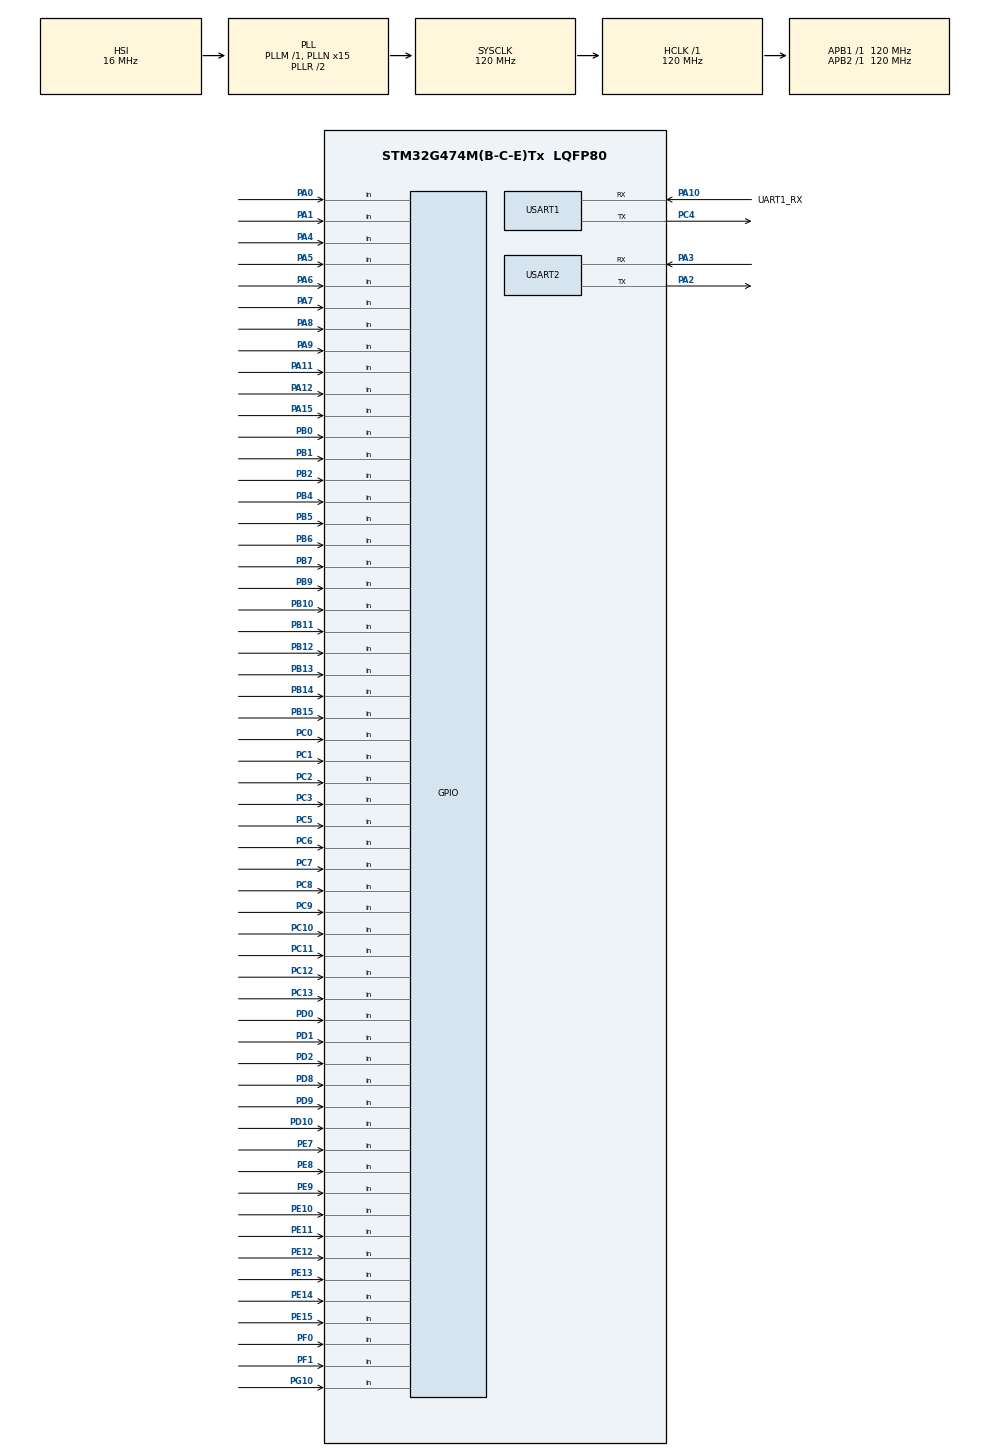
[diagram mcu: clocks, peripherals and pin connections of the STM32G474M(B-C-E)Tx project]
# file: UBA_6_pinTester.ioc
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FATFS._CODE_PAGE=850
FATFS._FS_NORTC=1
FATFS._FS_TINY=0
FATFS._MAX_SS=512
FATFS._MIN_SS=512
Mcu.Family=STM32G4
Mcu.Name=STM32G474M(B-C-E)Tx
Mcu.Package=LQFP80
NVIC.PriorityGroup=NVIC_PRIORITYGROUP_4
NVIC.USART2_IRQn=true\:0\:0\:false\:false\:true\:true\:true\:true
PA0.GPIO_Mode=GPIO_MODE_INPUT
PA0.GPIO_PuPd=GPIO_NOPULL
PA0.Signal=GPIO_Input
PA1.Signal=GPIO_Input
PA10.GPIO_Label=UART1_RX
PA10.Mode=Asynchronous
PA10.Signal=USART1_RX
PA11.Signal=GPIO_Input
PA12.Signal=GPIO_Input
PA13.GPIO_Label=SWDIO
PA13.Mode=Serial_Wire
PA13.Signal=SYS_JTMS-SWDIO
PA14.GPIO_Label=SWCLK
PA14.Mode=Serial_Wire
PA14.Signal=SYS_JTCK-SWCLK
PA15.Signal=GPIO_Input
PA2.Mode=Asynchronous
PA2.Signal=USART2_TX
PA3.Mode=Asynchronous
PA3.Signal=USART2_RX
PA4.Signal=GPIO_Input
PA5.Signal=GPIO_Input
PA6.Signal=GPIO_Input
PA7.Signal=GPIO_Input
PA8.Signal=GPIO_Input
PA9.Signal=GPIO_Input
PB0.Signal=GPIO_Input
PB1.Signal=GPIO_Input
PB10.Signal=GPIO_Input
PB11.Signal=GPIO_Input
PB12.Signal=GPIO_Input
PB13.Signal=GPIO_Input
PB14.Signal=GPIO_Input
PB15.Signal=GPIO_Input
PB2.Signal=GPIO_Input
PB3.GPIO_Label=SWO
PB3.Signal=SYS_JTDO-SWO
PB4.Signal=GPIO_Input
PB5.Signal=GPIO_Input
PB6.Signal=GPIO_Input
PB7.Signal=GPIO_Input
PB9.Signal=GPIO_Input
PC0.Signal=GPIO_Input
PC1.Signal=GPIO_Input
PC10.Signal=GPIO_Input
PC11.Signal=GPIO_Input
PC12.Signal=GPIO_Input
PC13.Signal=GPIO_Input
PC14-OSC32_IN.Mode=LSE-External-Oscillator
PC14-OSC32_IN.Signal=RCC_OSC32_IN
PC15-OSC32_OUT.Mode=LSE-External-Oscillator
PC15-OSC32_OUT.Signal=RCC_OSC32_OUT
PC2.Signal=GPIO_Input
PC3.Signal=GPIO_Input
PC4.Mode=Asynchronous
PC4.Signal=USART1_TX
PC5.Signal=GPIO_Input
PC6.Signal=GPIO_Input
PC7.Signal=GPIO_Input
PC8.Signal=GPIO_Input
PC9.Signal=GPIO_Input
PD0.Signal=GPIO_Input
PD1.Signal=GPIO_Input
PD10.Signal=GPIO_Input
PD2.Signal=GPIO_Input
PD8.Signal=GPIO_Input
PD9.Signal=GPIO_Input
PE10.Signal=GPIO_Input
PE11.Signal=GPIO_Input
PE12.Signal=GPIO_Input
PE13.Signal=GPIO_Input
PE14.Signal=GPIO_Input
PE15.Signal=GPIO_Input
PE7.Signal=GPIO_Input
PE8.Signal=GPIO_Input
PE9.Signal=GPIO_Input
PF0-OSC_IN.Signal=GPIO_Input
PF1-OSC_OUT.Signal=GPIO_Input
PG10-NRST.Signal=GPIO_Input
ProjectManager.HeapSize=0x200
ProjectManager.StackSize=0x400
ProjectManager.TargetToolchain=STM32CubeIDE
RCC.ADC12Freq_Value=120000000
RCC.ADC345Freq_Value=120000000
RCC.AHBFreq_Value=120000000
RCC.APB1Freq_Value=120000000
RCC.APB1TimFreq_Value=120000000
RCC.APB2Freq_Value=120000000
RCC.APB2TimFreq_Value=120000000
RCC.CortexFreq_Value=120000000
RCC.EXTERNAL_CLOCK_VALUE=12288000
RCC.HCLKFreq_Value=120000000
RCC.HSE_VALUE=8000000
RCC.HSI48_VALUE=48000000
RCC.HSI_VALUE=16000000
RCC.PLLN=15
RCC.SYSCLKFreq_VALUE=120000000
RCC.SYSCLKSource=RCC_SYSCLKSOURCE_PLLCLK
RCC.USART1CLockSelection=RCC_USART1CLKSOURCE_SYSCLK
RCC.USBFreq_Value=120000000
RCC.VCOOutputFreq_Value=240000000
STMicroelectronics.X-CUBE-DISPLAY.3.0.0_IsPackSelfContextualization=true
SYS.PVDLevel=PWR_PVDLEVEL_6
USART1.SwapParam=ADVFEATURE_SWAP_ENABLE
USART1.VirtualMode-Asynchronous=VM_ASYNC
USART2.VirtualMode-Asynchronous=VM_ASYNC
VP_FATFS_VS_Generic.Mode=User_defined
VP_RCC_VS_LSE.Mode=CRS SYNC Source LSE
VP_RTC_VS_RTC_Activate.Mode=RTC_Enabled
VP_RTC_VS_RTC_Calendar.Mode=RTC_Calendar
VP_SYS_VS_DBSignals.Mode=DisableDeadBatterySignals
VP_SYS_V_PVD_IN.Mode=Mode_PVD_Int
VP_SYS_V_VREFBUF.Mode=ExternalMode
board=custom

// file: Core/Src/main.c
/* USER CODE BEGIN Header */
/**
  ******************************************************************************
  * @file           : main.c
  * @brief          : Main program body
  ******************************************************************************
  * @attention
  *
  * Copyright (c) 2024 STMicroelectronics.
  * All rights reserved.
  *
  * This software is licensed under terms that can be found in the LICENSE file
  * in the root directory of this software component.
  * If no LICENSE file comes with this software, it is provided AS-IS.
  *
  ******************************************************************************
  */
/* USER CODE END Header */
#include "main.h"
#include "app_fatfs.h"
#include "rtc.h"
#include "usart.h"
#include "gpio.h"

/* USER CODE BEGIN Includes */
#include "uart_log.h"
#include "UBA_util.h"
#include "UBA_pin_test_UART.h"
/* USER CODE END Includes */

void SystemClock_Config(void);

int main(void)
{

  /* MCU Configuration--------------------------------------------------------*/

  /* Reset of all peripherals, Initializes the Flash interface and the Systick. */
  HAL_Init();

  /* Configure the system clock */
  SystemClock_Config();

  /* Initialize all configured peripherals */
  MX_GPIO_Init();
  if (MX_FATFS_Init() != APP_OK) {
    Error_Handler();
  }
  MX_USART2_UART_Init();
  MX_USART1_UART_Init();
  MX_RTC_Init();
  /* USER CODE BEGIN 2 */
  UBA_pin_test_init();
  UART_LOG_WARNNING("MAIN","Start Pin Test Prog");
  /* USER CODE END 2 */

  /* Infinite loop */
  while (1)
  {

  }
}

void SystemClock_Config(void)
{
  RCC_OscInitTypeDef RCC_OscInitStruct = {0};
  RCC_ClkInitTypeDef RCC_ClkInitStruct = {0};
  RCC_CRSInitTypeDef pInit = {0};

  /** Configure the main internal regulator output voltage
  */
  HAL_PWREx_ControlVoltageScaling(PWR_REGULATOR_VOLTAGE_SCALE1);

  /** Initializes the RCC Oscillators according to the specified parameters
  * in the RCC_OscInitTypeDef structure.
  */
  RCC_OscInitStruct.OscillatorType = RCC_OSCILLATORTYPE_HSI|RCC_OSCILLATORTYPE_LSI;
  RCC_OscInitStruct.HSIState = RCC_HSI_ON;
  RCC_OscInitStruct.HSICalibrationValue = RCC_HSICALIBRATION_DEFAULT;
  RCC_OscInitStruct.LSIState = RCC_LSI_ON;
  RCC_OscInitStruct.PLL.PLLState = RCC_PLL_ON;
  RCC_OscInitStruct.PLL.PLLSource = RCC_PLLSOURCE_HSI;
  RCC_OscInitStruct.PLL.PLLM = RCC_PLLM_DIV1;
  RCC_OscInitStruct.PLL.PLLN = 15;
  RCC_OscInitStruct.PLL.PLLP = RCC_PLLP_DIV2;
  RCC_OscInitStruct.PLL.PLLQ = RCC_PLLQ_DIV2;
  RCC_OscInitStruct.PLL.PLLR = RCC_PLLR_DIV2;
  if (HAL_RCC_OscConfig(&RCC_OscInitStruct) != HAL_OK)
  {
    Error_Handler();
  }

  /** Initializes the CPU, AHB and APB buses clocks
  */
  RCC_ClkInitStruct.ClockType = RCC_CLOCKTYPE_HCLK|RCC_CLOCKTYPE_SYSCLK
                              |RCC_CLOCKTYPE_PCLK1|RCC_CLOCKTYPE_PCLK2;
  RCC_ClkInitStruct.SYSCLKSource = RCC_SYSCLKSOURCE_PLLCLK;
  RCC_ClkInitStruct.AHBCLKDivider = RCC_SYSCLK_DIV1;
  RCC_ClkInitStruct.APB1CLKDivider = RCC_HCLK_DIV1;
  RCC_ClkInitStruct.APB2CLKDivider = RCC_HCLK_DIV1;

  if (HAL_RCC_ClockConfig(&RCC_ClkInitStruct, FLASH_LATENCY_3) != HAL_OK)
  {
    Error_Handler();
  }

  /** Enable the SYSCFG APB clock
  */
  __HAL_RCC_CRS_CLK_ENABLE();

  /** Configures CRS
  */
  pInit.Prescaler = RCC_CRS_SYNC_DIV1;
  pInit.Source = RCC_CRS_SYNC_SOURCE_LSE;
  pInit.Polarity = RCC_CRS_SYNC_POLARITY_RISING;
  pInit.ReloadValue = __HAL_RCC_CRS_RELOADVALUE_CALCULATE(48000000,32768);
  pInit.ErrorLimitValue = 34;
  pInit.HSI48CalibrationValue = 32;

  HAL_RCCEx_CRSConfig(&pInit);
}

void Error_Handler(void)
{
  __disable_irq();
  while (1)
  {
  }
}
